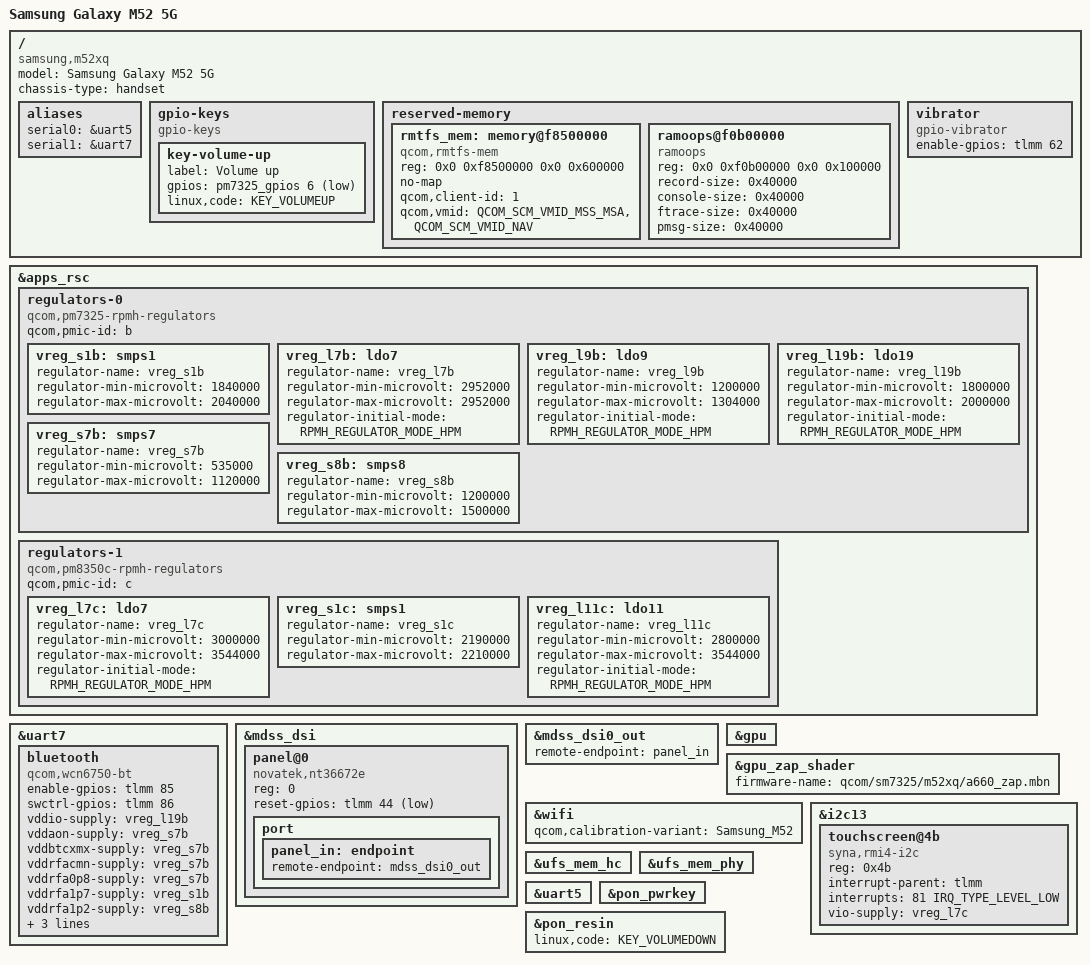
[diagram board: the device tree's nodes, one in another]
// SPDX-License-Identifier: BSD-3-Clause
/*
 * Черновик device tree для Samsung Galaxy M52 5G (m52xq / SM-M526B).
 * Основано на qcm6490-fairphone-fp5.dts (та же платформа Qualcomm "yupik",
 * SM7325/QCM6490 семейство) как шаблон. НЕ ГОТОВО К ЗАГРУЗКЕ — черновик,
 * начало работы 2026-08-02.
 *
 * Реальное железо M52 (найдено в downstream m52xq_eur_open_w00_r05.dts,
 * LineageOS/android_kernel_samsung_sm7325, ветка lineage-23.2):
 *   - Заряд/fuel gauge: SM5714 + PCA9468 (direct charging)
 *     -> В MAINLINE ДРАЙВЕРА НЕТ (проверено grep по drivers/power/,
 *        drivers/iio/ в этом дереве, 2026-08-02). БЛОКЕР для зарядки.
 *   - PMIC-регуляторы: серия PM8008 (как и у FP5 — совпадает!)
 *   - Экран: Novatek NT36672E, 1080x2400, до 144Гц
 *     -> Драйвер ЕСТЬ: drivers/gpu/drm/panel/panel-novatek-nt36672e.c
 *   - Тачскрин: Synaptics (synaptics_ts.ko) или STM (stm_ts.ko) в разных
 *     вариантах платы
 *     -> RMI4 (Synaptics) драйвер есть (drivers/input/rmi4/,
 *        syna,rmi4-i2c / syna,rmi4-spi), НЕ подтверждена совместимость
 *        протокола (Samsung иногда кастомизирует поверх той же микросхемы)
 *     -> STM: stmfts.c/stmpe-ts.c есть, тоже не подтверждено
 *   - Отпечаток: ET523 -> драйвера в mainline нет, отпечаток почти
 *     никогда не мейнлайнят, для первой загрузки не нужен
 *   - Аудио: Bolero + WCD938x -> драйвер ЕСТЬ: sound/soc/codecs/wcd938x.c
 *   - Плата (BOARD_NAME из LineageOS BoardConfig.mk): SRPUF17B001
 *
 * TODO (по порядку, каждый пункт += компиляция и, когда будет UART,
 * реальный тест):
 *   1. Заменить &wifi секцию -- проверить, тот же ли класс WiFi-чипа что
 *      и у FP5 (mainline-совместимый) или закрытый (как в downstream
 *      qca_cld3_wlan.ko -- если так, WiFi тут тоже не заработает)
 *   2. Заменить панель на nt36672e (drm/panel-novatek-nt36672e.c) с
 *      реальными GPIO/supply из downstream DTS
 *   3. Заменить touchscreen@0 на реальный чип этой платы/ревизии, с
 *      реальными GPIO/supply
 *   4. Решить вопрос заряда (SM5714/PCA9468) -- либо писать драйвер, либо
 *      временно убрать всю charger-секцию (грузиться без управления
 *      зарядом, только на текущем заряде батареи)
 *   5. Проверить/заменить PMIC regulator voltage-таблицы -- взяты из FP5,
 *      почти наверняка НЕ совпадают с реальными для M52 (другая плата)
 *   6. Убрать всё камеро-специфичное (cci0/cci1 секции) -- под другие,
 *      не M52, камеры -- заменить позже отдельно
 *   7. Убрать vibrator@5a (awinic aw86927) -- проверить реальный чип
 *      вибромотора M52
 *
 * Источники (проверено 2026-08-02):
 *   https://github.com/sc7280-mainline/linux (форк, в котором лежит этот файл)
 *   https://github.com/LineageOS/android_kernel_samsung_sm7325 (ветка lineage-23.2)
 *   https://github.com/LineageOS/android_device_samsung_m52xq (ветка lineage-23.2)
 *   https://github.com/LineageOS/android_device_samsung_sm7325-common
 */

/dts-v1/;

#define PM7250B_SID 8
#define PM7250B_SID1 9

#include <dt-bindings/iio/qcom,spmi-adc7-pm7325.h>
#include <dt-bindings/iio/qcom,spmi-adc7-pmk8350.h>
#include <dt-bindings/leds/common.h>
#include <dt-bindings/media/video-interfaces.h>
#include <dt-bindings/pinctrl/qcom,pmic-gpio.h>
#include <dt-bindings/regulator/qcom,rpmh-regulator.h>
#include <dt-bindings/sound/qcom,q6asm.h>
#include <dt-bindings/sound/qcom,q6dsp-lpass-ports.h>
#include "kodiak.dtsi"
#include "pm7250b.dtsi"
#include "pm7325.dtsi"
#include "pm8350c.dtsi"
#include "pmk8350.dtsi"

/delete-node/ &rmtfs_mem;

/ {
	model = "Samsung Galaxy M52 5G";
	compatible = "samsung,m52xq", "qcom,qcm6490";
	chassis-type = "handset";

	aliases {
		serial0 = &uart5;
		serial1 = &uart7;
	};

	/*
	 * ЗАГЛУШКА: скопировано из FP5 без изменений. WCD938x подтверждён
	 * (реальный чип M52), но конкретные GPIO/supply/micbias-напряжения
	 * НЕ проверены под M52 -- нужно сверить с downstream DTS отдельно.
	 */
	/*
	 * ВРЕМЕННО ОТКЛЮЧЕНО в этом черновике: узел ссылался на &wcd_reset_n,
	 * &vreg_l18b/&vreg_l17b/&vreg_bob, &wcd_rx/&wcd_tx -- все они были в
	 * секциях (&tlmm pinctrl, вторые regulators, &swr0/&swr1), которые
	 * в этом урезанном черновике ещё не перенесены с FP5. Возвращать
	 * вместе с этими секциями, когда дойдём до аудио.
	 */

	gpio-keys {
		compatible = "gpio-keys";

		key-volume-up {
			label = "Volume up";
			gpios = <&pm7325_gpios 6 GPIO_ACTIVE_LOW>; /* TODO: проверить под M52 */
			linux,code = <KEY_VOLUMEUP>;
		};
	};

	reserved-memory {
		/* TODO: полностью заменить на реальные регионы из downstream DTS M52 --
		 * эти адреса/размеры взяты с FP5 и почти наверняка неверны */
		rmtfs_mem: memory@f8500000 {
			compatible = "qcom,rmtfs-mem";
			reg = <0x0 0xf8500000 0x0 0x600000>;
			no-map;

			qcom,client-id = <1>;
			qcom,vmid = <QCOM_SCM_VMID_MSS_MSA>, <QCOM_SCM_VMID_NAV>;
		};

		/* Адрес и размеры -- РЕАЛЬНЫЕ, из downstream
		 * m52xq_eur_open_w00_r05.dts (ramoops@F0B00000), не с FP5.
		 * Фиксированный HW-карвaут, должен быть одинаковым независимо
		 * от того, какая ОС на нём работает. */
		ramoops@f0b00000 {
			compatible = "ramoops";
			reg = <0x0 0xf0b00000 0x0 0x100000>;
			record-size = <0x40000>;
			console-size = <0x40000>;
			ftrace-size = <0x40000>;
			pmsg-size = <0x40000>;
		};
	};

	/* Простой GPIO-вибратор (COINDC), подтверждено в downstream:
	 * dc_vibrator { compatible = "samsung,dc_vibrator";
	 * dc_vib,gpio_en = <TLMM pin 62, flag 0>; }. Mainline-биндинг
	 * "gpio-vibrator" -- уже используется на других устройствах
	 * (например msm8916-samsung-gt58.dts) -- подходит напрямую, без
	 * доп. драйвера. */
	vibrator {
		compatible = "gpio-vibrator";
		enable-gpios = <&tlmm 62 GPIO_ACTIVE_HIGH>;
	};
};

&apps_rsc {
	/* ЗАГЛУШКА: regulator voltage-таблицы скопированы с FP5 без изменений.
	 * ТРЕБУЕТ ПРОВЕРКИ под реальную плату M52 -- это один из самых
	 * рискованных не проверенных участков (неверное питание может
	 * повредить периферию). */
	regulators-0 {
		compatible = "qcom,pm7325-rpmh-regulators";
		qcom,pmic-id = "b";

		vreg_s1b: smps1 {
			regulator-name = "vreg_s1b";
			regulator-min-microvolt = <1840000>;
			regulator-max-microvolt = <2040000>;
		};

		vreg_l7b: ldo7 {
			regulator-name = "vreg_l7b";
			regulator-min-microvolt = <2952000>;
			regulator-max-microvolt = <2952000>;
			regulator-initial-mode = <RPMH_REGULATOR_MODE_HPM>;
		};

		vreg_l9b: ldo9 {
			regulator-name = "vreg_l9b";
			regulator-min-microvolt = <1200000>;
			regulator-max-microvolt = <1304000>;
			regulator-initial-mode = <RPMH_REGULATOR_MODE_HPM>;
		};

		/* Ниже -- добавлены для bluetooth (qcom,wcn6750-bt), значения
		 * из БАЗОВОГО yupik-regulators.dtsi платформы, не с FP5. */
		vreg_l19b: ldo19 {
			regulator-name = "vreg_l19b";
			regulator-min-microvolt = <1800000>;
			regulator-max-microvolt = <2000000>;
			regulator-initial-mode = <RPMH_REGULATOR_MODE_HPM>;
		};

		vreg_s7b: smps7 {
			regulator-name = "vreg_s7b";
			regulator-min-microvolt = <535000>;
			regulator-max-microvolt = <1120000>;
		};

		vreg_s8b: smps8 {
			regulator-name = "vreg_s8b";
			regulator-min-microvolt = <1200000>;
			regulator-max-microvolt = <1500000>;
		};
	};

	/* pm8350c_l7 -- питание touchscreen (tsp_io_ldo). Значение взято
	 * из БАЗОВОГО yupik-regulators.dtsi (SoC-платформа, не FP5), т.е.
	 * это не "скопировано с чужого телефона", а платформенный допуск --
	 * см. ту же логику, что и для vreg_s1b/l9b выше. */
	regulators-1 {
		compatible = "qcom,pm8350c-rpmh-regulators";
		qcom,pmic-id = "c";

		vreg_l7c: ldo7 {
			regulator-name = "vreg_l7c";
			regulator-min-microvolt = <3000000>;
			regulator-max-microvolt = <3544000>;
			regulator-initial-mode = <RPMH_REGULATOR_MODE_HPM>;
		};

		/* для bluetooth */
		vreg_s1c: smps1 {
			regulator-name = "vreg_s1c";
			regulator-min-microvolt = <2190000>;
			regulator-max-microvolt = <2210000>;
		};

		vreg_l11c: ldo11 {
			regulator-name = "vreg_l11c";
			regulator-min-microvolt = <2800000>;
			regulator-max-microvolt = <3544000>;
			regulator-initial-mode = <RPMH_REGULATOR_MODE_HPM>;
		};
	};
};

/*
 * Bluetooth: тот же чип WCN6750, что и WiFi (combo-кристалл). В
 * базовом yupik.dtsi (платформенный уровень, НЕ board-специфичный
 * файл M52) уже есть готовый узел bt_wcn6750 с compatible =
 * "qcom,wcn6750-bt" -- ТЕ ЖЕ пины, что и в mainline-конфиге FP5:
 * BT_EN=85, SW_CTRL=86 (совпадение подтверждено напрямую, не
 * предположение). Узел ниже -- перенос по образцу FP5 (тот же UART7),
 * с этими подтверждёнными пинами.
 */
&uart7 {
	status = "okay";

	bluetooth: bluetooth {
		compatible = "qcom,wcn6750-bt";

		enable-gpios = <&tlmm 85 GPIO_ACTIVE_HIGH>;
		swctrl-gpios = <&tlmm 86 GPIO_ACTIVE_HIGH>;

		vddio-supply = <&vreg_l19b>;
		vddaon-supply = <&vreg_s7b>;
		vddbtcxmx-supply = <&vreg_s7b>;
		vddrfacmn-supply = <&vreg_s7b>;
		vddrfa0p8-supply = <&vreg_s7b>;
		vddrfa1p7-supply = <&vreg_s1b>;
		vddrfa1p2-supply = <&vreg_s8b>;
		vddrfa2p2-supply = <&vreg_s1c>;
		vddasd-supply = <&vreg_l11c>;

		max-speed = <3200000>;
		/* TODO: pinctrl-0/pinctrl-names у FP5 ссылаются на
		 * bluetooth_enable_default/sw_ctrl_default -- эти pinctrl-узлы
		 * определены в FP5-специфичной &tlmm секции, которую мы в этот
		 * черновик не переносили. Без pinctrl, вероятно, заработает
		 * (gpiod задаст режим напрямую), но не "по всем правилам". */
	};
};

/*
 * Панель, ревизия r05: reset-gpio подтверждён -- во всех 5 вариантах
 * nt36672e (60/90/120/144Hz, cphy) в downstream DTS одно и то же:
 * TLMM pin 44, active-low.
 *
 * ПРОВЕРЕНО ГОРАЗДО ТВЁРЖЕ, ЧЕМ ОЖИДАЛОСЬ: сравнил hardcoded таймdescriptor
 * mainline-драйвера drivers/gpu/drm/panel/panel-novatek-nt36672e.c
 * (nt36672e_1080x2408_60hz: hfp=76 hpw=12 hbp=56, vfp=46 vpw=10 vbp=10)
 * с реальными downstream-порчами M52 из фрагмента
 * qcom,mdss_dsi_nt36672e_fhd_plus_60_video -- ЧИСЛА СОВПАДАЮТ ТОЧНО,
 * ЦИФРА В ЦИФРУ. Дополнительно сравнил байт-код init-последовательности
 * (qcom,mdss-dsi-on-command той же секции, 262 DCS-команды) с
 * hardcoded init-функцией драйвера -- содержимое практически идентично
 * (отличия только в оформлении page-switch макросов, не в данных).
 * Вывод: mainline-драйвер, судя по всему, написан для ТОЧНО ТОЙ ЖЕ
 * панели (или её ближайшего родственника), что стоит в M52 в 60Hz-
 * режиме. compatible = "novatek,nt36672e" оставлен как есть, БЕЗ
 * патчинга драйвера -- реальный шанс, что заработает из коробки.
 * 90/120/144Hz-режимы для первого теста сознательно не рассматриваются
 * (сложнее, отдельная DFPS-настройка, выше риск).
 */
&mdss_dsi {
	status = "okay";

	panel@0 {
		compatible = "novatek,nt36672e"; /* TODO: точная compatible-строка,
			возможно понадобится доп. модельный суффикс */
		reg = <0>;
		reset-gpios = <&tlmm 44 GPIO_ACTIVE_LOW>; /* подтверждено downstream DTS */
		/* TODO: vci/vddio/dvdd-supply -- в downstream заданы через
		 * qcom,panel-supply-entries (0x33 записей, ссылается на
		 * отдельный vreg-def блок, не разобран за это время) */

		port {
			panel_in: endpoint {
				remote-endpoint = <&mdss_dsi0_out>;
			};
		};
	};
};

&mdss_dsi0_out {
	remote-endpoint = <&panel_in>;
};

&gpu {
	status = "okay";
};

&gpu_zap_shader {
	/* Тот же Adreno a660, что и у FP5 -- путь к прошивке скорее всего
	 * можно оставить в этом же формате, но нужен реальный .mbn файл
	 * под M52 (взять из vendor/firmware M52 или собрать из
	 * зеркалированного /vendor/firmware, как это уже сделано в
	 * параллельном Halium-проекте на этом же устройстве). */
	firmware-name = "qcom/sm7325/m52xq/a660_zap.mbn";
};

&wifi {
	/* Чип подтверждён: downstream defconfig (lineage-m52xq_defconfig)
	 * содержит CONFIG_QCA_CLD_WLAN_DYNAMIC_SINGLE_CHIP_NAME="qca6750" +
	 * CONFIG_CNSS_QCA6750=y -- это Samsung-внутреннее имя для чипа
	 * WCN6750, для которого в mainline уже есть зрелый драйвер ath11k
	 * (compatible = "qcom,wcn6750-wifi", уже описан в базовом
	 * kodiak.dtsi, который этот файл подключает). Точно тот же чип
	 * использует Fairphone 5 на этой же платформе (см.
	 * qcm6490-fairphone-fp5.dts: &wifi { qcom,calibration-variant =
	 * "Fairphone_5"; status = "okay"; }).
	 *
	 * Board-специфичный калибровочный firmware-блоб для M52 уже
	 * извлечён в параллельном Halium-проекте на этом устройстве:
	 * /home/sasha/halium-backup/m52xq/proprietary/vendor/firmware/qca6750/bdwlan.elf
	 * -- нужно положить в initramfs/rootfs как
	 * /lib/firmware/ath11k/WCN6750/hw1.0/board-2.bin (или под именем,
	 * которое ath11k подберёт по qcom,calibration-variant -- уточнить
	 * точный механизм сопоставления перед первым тестом). Остальные
	 * компоненты прошивки WCN6750 (wlanmdsp/m3/regdb) chip-общие, не
	 * board-специфичные -- ожидаются из пакета linux-firmware.
	 */
	qcom,calibration-variant = "Samsung_M52";
	status = "okay";
};

/*
 * Тачскрин, ревизия платы r05 (та, что реально проверена в downstream
 * DTS): Synaptics S3908 на i2c13 (QUP SE13), адрес 0x4b. Данные взяты
 * напрямую из фрагмента@97 в m52xq_eur_open_w00_r05.dts + phandle-
 * символов (fixed_regulator0, pm8350c_l7).
 *
 * ВАЖНАЯ ОГОВОРКА: downstream-драйвер здесь -- НЕ обычный протокол
 * Synaptics RMI4, а Samsung-специфичная обвязка "sec_input"
 * (свойства вроде sec,tclm_level/enable_settings_aot/support_fod
 * это Samsung DeX/fingerprint-on-display функции, не часть
 * стандартного RMI4). Firmware-блобы (s3908_m52xq_sdc.bin/boe.bin --
 * два варианта под разных поставщиков панели, SDC/BOE) почти
 * наверняка кастомные под этот Samsung-стек, а не эталонный RMI4-
 * образ. Ниже -- узел под стандартный mainline-биндинг
 * "syna,rmi4-i2c" (auto-discovery функций через PDT-скан, без
 * захардкоженных rmi4-fXX подузлов). Скомпилируется и, вероятно,
 * даже отзовётся на i2c-пробинге (адрес совпадает), но заговорит ли
 * реально по стандартному RMI4-протоколу с этой прошивкой -- ЧИСТО
 * не проверено, узнаваемо только на реальном железе.
 *
 * У другой ревизии платы (видно по firmware/tsp_stm/fts5cu56a_m52xq.bin
 * в downstream-дереве) стоит STM FTS5CU56A вместо Synaptics -- какая
 * именно ревизия в конкретном экземпляре устройства, неизвестно,
 * нужно проверять на месте (например по board-id в загрузочных логах).
 */
&i2c13 {
	status = "okay";

	touchscreen@4b {
		compatible = "syna,rmi4-i2c";
		reg = <0x4b>;
		#address-cells = <1>;
		#size-cells = <0>;

		interrupt-parent = <&tlmm>;
		interrupts = <81 IRQ_TYPE_LEVEL_LOW>; /* пин подтверждён (gpio81), полярность -- предположение */

		vio-supply = <&vreg_l7c>; /* было tsp_io_ldo-supply, подтверждено по symbols */
		/* TODO: tsp_avdd_ldo-supply в downstream -- GPIO-управляемый
		 * fixed_regulator0 (TLMM pin 106, active-high), не PMIC LDO --
		 * нужен отдельный regulator-fixed узел, сюда не перенесён. */
	};
};

&ufs_mem_hc {
	status = "okay";
	/* TODO: reset-gpios, vcc/vccq-supply под M52 */
};

&ufs_mem_phy {
	status = "okay";
};

&uart5 {
	status = "okay";
};

&pon_pwrkey {
	status = "okay";
};

&pon_resin {
	linux,code = <KEY_VOLUMEDOWN>;
	status = "okay";
};

/*
 * СОЗНАТЕЛЬНО ПРОПУЩЕНО в этом черновике (нужна отдельная работа):
 *   - &camss / &cci0 / &cci1 -- камеры M52 совсем другие, весь блок с FP5 удалён
 *   - зарядка (SM5714/PCA9468) -- драйвера в mainline нет, секции нет вовсе
 *   - тачскрин -- нет уверенности в правильном chip/protocol, не включен
 *   - vibrator -- чип не проверен, не включен
 *   - NFC/Bluetooth -- не проверено отдельно, скопировано с FP5 в первом
 *     черновике только частично (bluetooth ниже, требует проверки чипа)
 */
